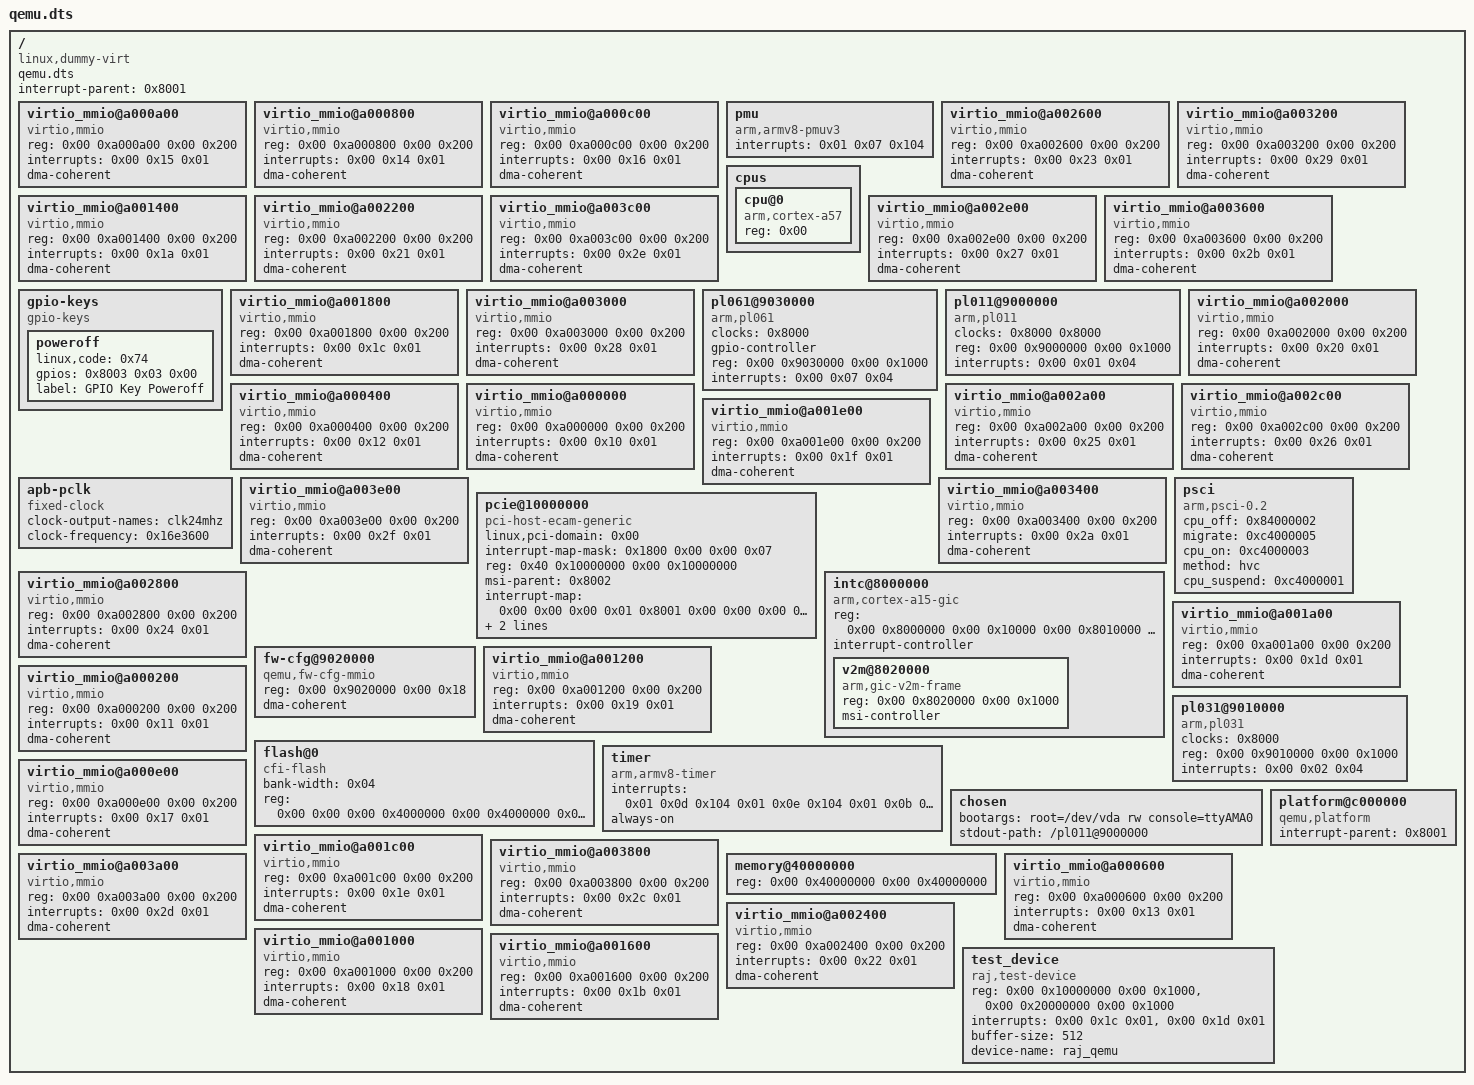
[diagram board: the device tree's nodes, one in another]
/dts-v1/;

/ {
	qemu.dts;
	compatible = "linux,dummy-virt";
	#address-cells = <0x02>;
	interrupt-parent = <0x8001>;
	#size-cells = <0x02>;

	virtio_mmio@a000a00 {
		reg = <0x00 0xa000a00 0x00 0x200>;
		compatible = "virtio,mmio";
		interrupts = <0x00 0x15 0x01>;
		dma-coherent;
	};

	virtio_mmio@a000800 {
		reg = <0x00 0xa000800 0x00 0x200>;
		compatible = "virtio,mmio";
		interrupts = <0x00 0x14 0x01>;
		dma-coherent;
	};

	virtio_mmio@a000c00 {
		reg = <0x00 0xa000c00 0x00 0x200>;
		compatible = "virtio,mmio";
		interrupts = <0x00 0x16 0x01>;
		dma-coherent;
	};

	pmu {
		compatible = "arm,armv8-pmuv3";
		interrupts = <0x01 0x07 0x104>;
	};

	virtio_mmio@a002600 {
		reg = <0x00 0xa002600 0x00 0x200>;
		compatible = "virtio,mmio";
		interrupts = <0x00 0x23 0x01>;
		dma-coherent;
	};

	virtio_mmio@a003200 {
		reg = <0x00 0xa003200 0x00 0x200>;
		compatible = "virtio,mmio";
		interrupts = <0x00 0x29 0x01>;
		dma-coherent;
	};

	virtio_mmio@a001400 {
		reg = <0x00 0xa001400 0x00 0x200>;
		compatible = "virtio,mmio";
		interrupts = <0x00 0x1a 0x01>;
		dma-coherent;
	};

	cpus {
		#address-cells = <0x01>;
		#size-cells = <0x00>;

		cpu@0 {
			device_type = "cpu";
			reg = <0x00>;
			compatible = "arm,cortex-a57";
		};
	};

	virtio_mmio@a002200 {
		reg = <0x00 0xa002200 0x00 0x200>;
		compatible = "virtio,mmio";
		interrupts = <0x00 0x21 0x01>;
		dma-coherent;
	};

	virtio_mmio@a003c00 {
		reg = <0x00 0xa003c00 0x00 0x200>;
		compatible = "virtio,mmio";
		interrupts = <0x00 0x2e 0x01>;
		dma-coherent;
	};

	virtio_mmio@a002e00 {
		reg = <0x00 0xa002e00 0x00 0x200>;
		compatible = "virtio,mmio";
		interrupts = <0x00 0x27 0x01>;
		dma-coherent;
	};

	virtio_mmio@a003600 {
		reg = <0x00 0xa003600 0x00 0x200>;
		compatible = "virtio,mmio";
		interrupts = <0x00 0x2b 0x01>;
		dma-coherent;
	};

	gpio-keys {
		compatible = "gpio-keys";
		#address-cells = <0x01>;
		#size-cells = <0x00>;

		poweroff {
			linux,code = <0x74>;
			gpios = <0x8003 0x03 0x00>;
			label = "GPIO Key Poweroff";
		};
	};

	virtio_mmio@a001800 {
		reg = <0x00 0xa001800 0x00 0x200>;
		compatible = "virtio,mmio";
		interrupts = <0x00 0x1c 0x01>;
		dma-coherent;
	};

	virtio_mmio@a003000 {
		reg = <0x00 0xa003000 0x00 0x200>;
		compatible = "virtio,mmio";
		interrupts = <0x00 0x28 0x01>;
		dma-coherent;
	};

	pl061@9030000 {
		clocks = <0x8000>;
		gpio-controller;
		#gpio-cells = <0x02>;
		clock-names = "apb_pclk";
		reg = <0x00 0x9030000 0x00 0x1000>;
		compatible = "arm,pl061\0arm,primecell";
		phandle = <0x8003>;
		interrupts = <0x00 0x07 0x04>;
	};

	pl011@9000000 {
		clocks = <0x8000 0x8000>;
		clock-names = "uartclk\0apb_pclk";
		reg = <0x00 0x9000000 0x00 0x1000>;
		compatible = "arm,pl011\0arm,primecell";
		interrupts = <0x00 0x01 0x04>;
	};

	virtio_mmio@a002000 {
		reg = <0x00 0xa002000 0x00 0x200>;
		compatible = "virtio,mmio";
		interrupts = <0x00 0x20 0x01>;
		dma-coherent;
	};

	virtio_mmio@a000400 {
		reg = <0x00 0xa000400 0x00 0x200>;
		compatible = "virtio,mmio";
		interrupts = <0x00 0x12 0x01>;
		dma-coherent;
	};

	virtio_mmio@a000000 {
		reg = <0x00 0xa000000 0x00 0x200>;
		compatible = "virtio,mmio";
		interrupts = <0x00 0x10 0x01>;
		dma-coherent;
	};

	virtio_mmio@a002a00 {
		reg = <0x00 0xa002a00 0x00 0x200>;
		compatible = "virtio,mmio";
		interrupts = <0x00 0x25 0x01>;
		dma-coherent;
	};

	virtio_mmio@a002c00 {
		reg = <0x00 0xa002c00 0x00 0x200>;
		compatible = "virtio,mmio";
		interrupts = <0x00 0x26 0x01>;
		dma-coherent;
	};

	virtio_mmio@a001e00 {
		reg = <0x00 0xa001e00 0x00 0x200>;
		compatible = "virtio,mmio";
		interrupts = <0x00 0x1f 0x01>;
		dma-coherent;
	};

	apb-pclk {
		clock-output-names = "clk24mhz";
		#clock-cells = <0x00>;
		compatible = "fixed-clock";
		phandle = <0x8000>;
		clock-frequency = <0x16e3600>;
	};

	virtio_mmio@a003e00 {
		reg = <0x00 0xa003e00 0x00 0x200>;
		compatible = "virtio,mmio";
		interrupts = <0x00 0x2f 0x01>;
		dma-coherent;
	};

	virtio_mmio@a003400 {
		reg = <0x00 0xa003400 0x00 0x200>;
		compatible = "virtio,mmio";
		interrupts = <0x00 0x2a 0x01>;
		dma-coherent;
	};

	pcie@10000000 {
		ranges = <0x1000000 0x00 0x00 0x00 0x3eff0000 0x00 0x10000 0x2000000 0x00 0x10000000 0x00 0x10000000 0x00 0x2eff0000 0x3000000 0x80 0x00 0x80 0x00 0x80 0x00>;
		linux,pci-domain = <0x00>;
		#interrupt-cells = <0x01>;
		device_type = "pci";
		interrupt-map-mask = <0x1800 0x00 0x00 0x07>;
		reg = <0x40 0x10000000 0x00 0x10000000>;
		msi-parent = <0x8002>;
		compatible = "pci-host-ecam-generic";
		#address-cells = <0x03>;
		interrupt-map = <0x00 0x00 0x00 0x01 0x8001 0x00 0x00 0x00 0x03 0x04 0x00 0x00 0x00 0x02 0x8001 0x00 0x00 0x00 0x04 0x04 0x00 0x00 0x00 0x03 0x8001 0x00 0x00 0x00 0x05 0x04 0x00 0x00 0x00 0x04 0x8001 0x00 0x00 0x00 0x06 0x04 0x800 0x00 0x00 0x01 0x8001 0x00 0x00 0x00 0x04 0x04 0x800 0x00 0x00 0x02 0x8001 0x00 0x00 0x00 0x05 0x04 0x800 0x00 0x00 0x03 0x8001 0x00 0x00 0x00 0x06 0x04 0x800 0x00 0x00 0x04 0x8001 0x00 0x00 0x00 0x03 0x04 0x1000 0x00 0x00 0x01 0x8001 0x00 0x00 0x00 0x05 0x04 0x1000 0x00 0x00 0x02 0x8001 0x00 0x00 0x00 0x06 0x04 0x1000 0x00 0x00 0x03 0x8001 0x00 0x00 0x00 0x03 0x04 0x1000 0x00 0x00 0x04 0x8001 0x00 0x00 0x00 0x04 0x04 0x1800 0x00 0x00 0x01 0x8001 0x00 0x00 0x00 0x06 0x04 0x1800 0x00 0x00 0x02 0x8001 0x00 0x00 0x00 0x03 0x04 0x1800 0x00 0x00 0x03 0x8001 0x00 0x00 0x00 0x04 0x04 0x1800 0x00 0x00 0x04 0x8001 0x00 0x00 0x00 0x05 0x04>;
		bus-range = <0x00 0xff>;
		#size-cells = <0x02>;
		dma-coherent;
	};

	psci {
		cpu_off = <0x84000002>;
		migrate = <0xc4000005>;
		cpu_on = <0xc4000003>;
		compatible = "arm,psci-0.2\0arm,psci";
		method = "hvc";
		cpu_suspend = <0xc4000001>;
	};

	virtio_mmio@a002800 {
		reg = <0x00 0xa002800 0x00 0x200>;
		compatible = "virtio,mmio";
		interrupts = <0x00 0x24 0x01>;
		dma-coherent;
	};

	intc@8000000 {
		ranges;
		#interrupt-cells = <0x03>;
		reg = <0x00 0x8000000 0x00 0x10000 0x00 0x8010000 0x00 0x10000>;
		compatible = "arm,cortex-a15-gic";
		#address-cells = <0x02>;
		phandle = <0x8001>;
		interrupt-controller;
		#size-cells = <0x02>;

		v2m@8020000 {
			reg = <0x00 0x8020000 0x00 0x1000>;
			msi-controller;
			compatible = "arm,gic-v2m-frame";
			phandle = <0x8002>;
		};
	};

	virtio_mmio@a001a00 {
		reg = <0x00 0xa001a00 0x00 0x200>;
		compatible = "virtio,mmio";
		interrupts = <0x00 0x1d 0x01>;
		dma-coherent;
	};

	fw-cfg@9020000 {
		reg = <0x00 0x9020000 0x00 0x18>;
		compatible = "qemu,fw-cfg-mmio";
		dma-coherent;
	};

	virtio_mmio@a001200 {
		reg = <0x00 0xa001200 0x00 0x200>;
		compatible = "virtio,mmio";
		interrupts = <0x00 0x19 0x01>;
		dma-coherent;
	};

	virtio_mmio@a000200 {
		reg = <0x00 0xa000200 0x00 0x200>;
		compatible = "virtio,mmio";
		interrupts = <0x00 0x11 0x01>;
		dma-coherent;
	};

	flash@0 {
		bank-width = <0x04>;
		reg = <0x00 0x00 0x00 0x4000000 0x00 0x4000000 0x00 0x4000000>;
		compatible = "cfi-flash";
	};

	timer {
		compatible = "arm,armv8-timer\0arm,armv7-timer";
		interrupts = <0x01 0x0d 0x104 0x01 0x0e 0x104 0x01 0x0b 0x104 0x01 0x0a 0x104>;
		always-on;
	};

	pl031@9010000 {
		clocks = <0x8000>;
		clock-names = "apb_pclk";
		reg = <0x00 0x9010000 0x00 0x1000>;
		compatible = "arm,pl031\0arm,primecell";
		interrupts = <0x00 0x02 0x04>;
	};

	virtio_mmio@a000e00 {
		reg = <0x00 0xa000e00 0x00 0x200>;
		compatible = "virtio,mmio";
		interrupts = <0x00 0x17 0x01>;
		dma-coherent;
	};

	chosen {
		bootargs = "root=/dev/vda rw console=ttyAMA0";
		stdout-path = "/pl011@9000000";
	};

	virtio_mmio@a001c00 {
		reg = <0x00 0xa001c00 0x00 0x200>;
		compatible = "virtio,mmio";
		interrupts = <0x00 0x1e 0x01>;
		dma-coherent;
	};

	virtio_mmio@a003800 {
		reg = <0x00 0xa003800 0x00 0x200>;
		compatible = "virtio,mmio";
		interrupts = <0x00 0x2c 0x01>;
		dma-coherent;
	};

	platform@c000000 {
		ranges = <0x00 0x00 0xc000000 0x2000000>;
		compatible = "qemu,platform\0simple-bus";
		#address-cells = <0x01>;
		interrupt-parent = <0x8001>;
		#size-cells = <0x01>;
	};

	memory@40000000 {
		device_type = "memory";
		reg = <0x00 0x40000000 0x00 0x40000000>;
	};

	virtio_mmio@a003a00 {
		reg = <0x00 0xa003a00 0x00 0x200>;
		compatible = "virtio,mmio";
		interrupts = <0x00 0x2d 0x01>;
		dma-coherent;
	};

	virtio_mmio@a000600 {
		reg = <0x00 0xa000600 0x00 0x200>;
		compatible = "virtio,mmio";
		interrupts = <0x00 0x13 0x01>;
		dma-coherent;
	};

	virtio_mmio@a002400 {
		reg = <0x00 0xa002400 0x00 0x200>;
		compatible = "virtio,mmio";
		interrupts = <0x00 0x22 0x01>;
		dma-coherent;
	};

	virtio_mmio@a001000 {
		reg = <0x00 0xa001000 0x00 0x200>;
		compatible = "virtio,mmio";
		interrupts = <0x00 0x18 0x01>;
		dma-coherent;
	};

	virtio_mmio@a001600 {
		reg = <0x00 0xa001600 0x00 0x200>;
		compatible = "virtio,mmio";
		interrupts = <0x00 0x1b 0x01>;
		dma-coherent;
	};

	test_device {
    	compatible = "raj,test-device";
    	status = "okay";
    	reg = < 0x00 0x10000000 0x00 0x1000>, 
    		  <	0x00 0x20000000 0x00 0x1000>;
    	reg-names = "control", "data";

    	interrupts = <0x00 0x1c 0x01>, <0x00 0x1d 0x01>;
    	interrupt-names = "rx_irq", "tx_irq";

    	buffer-size = <512>;
    	device-name = "raj_qemu";
    };
};
